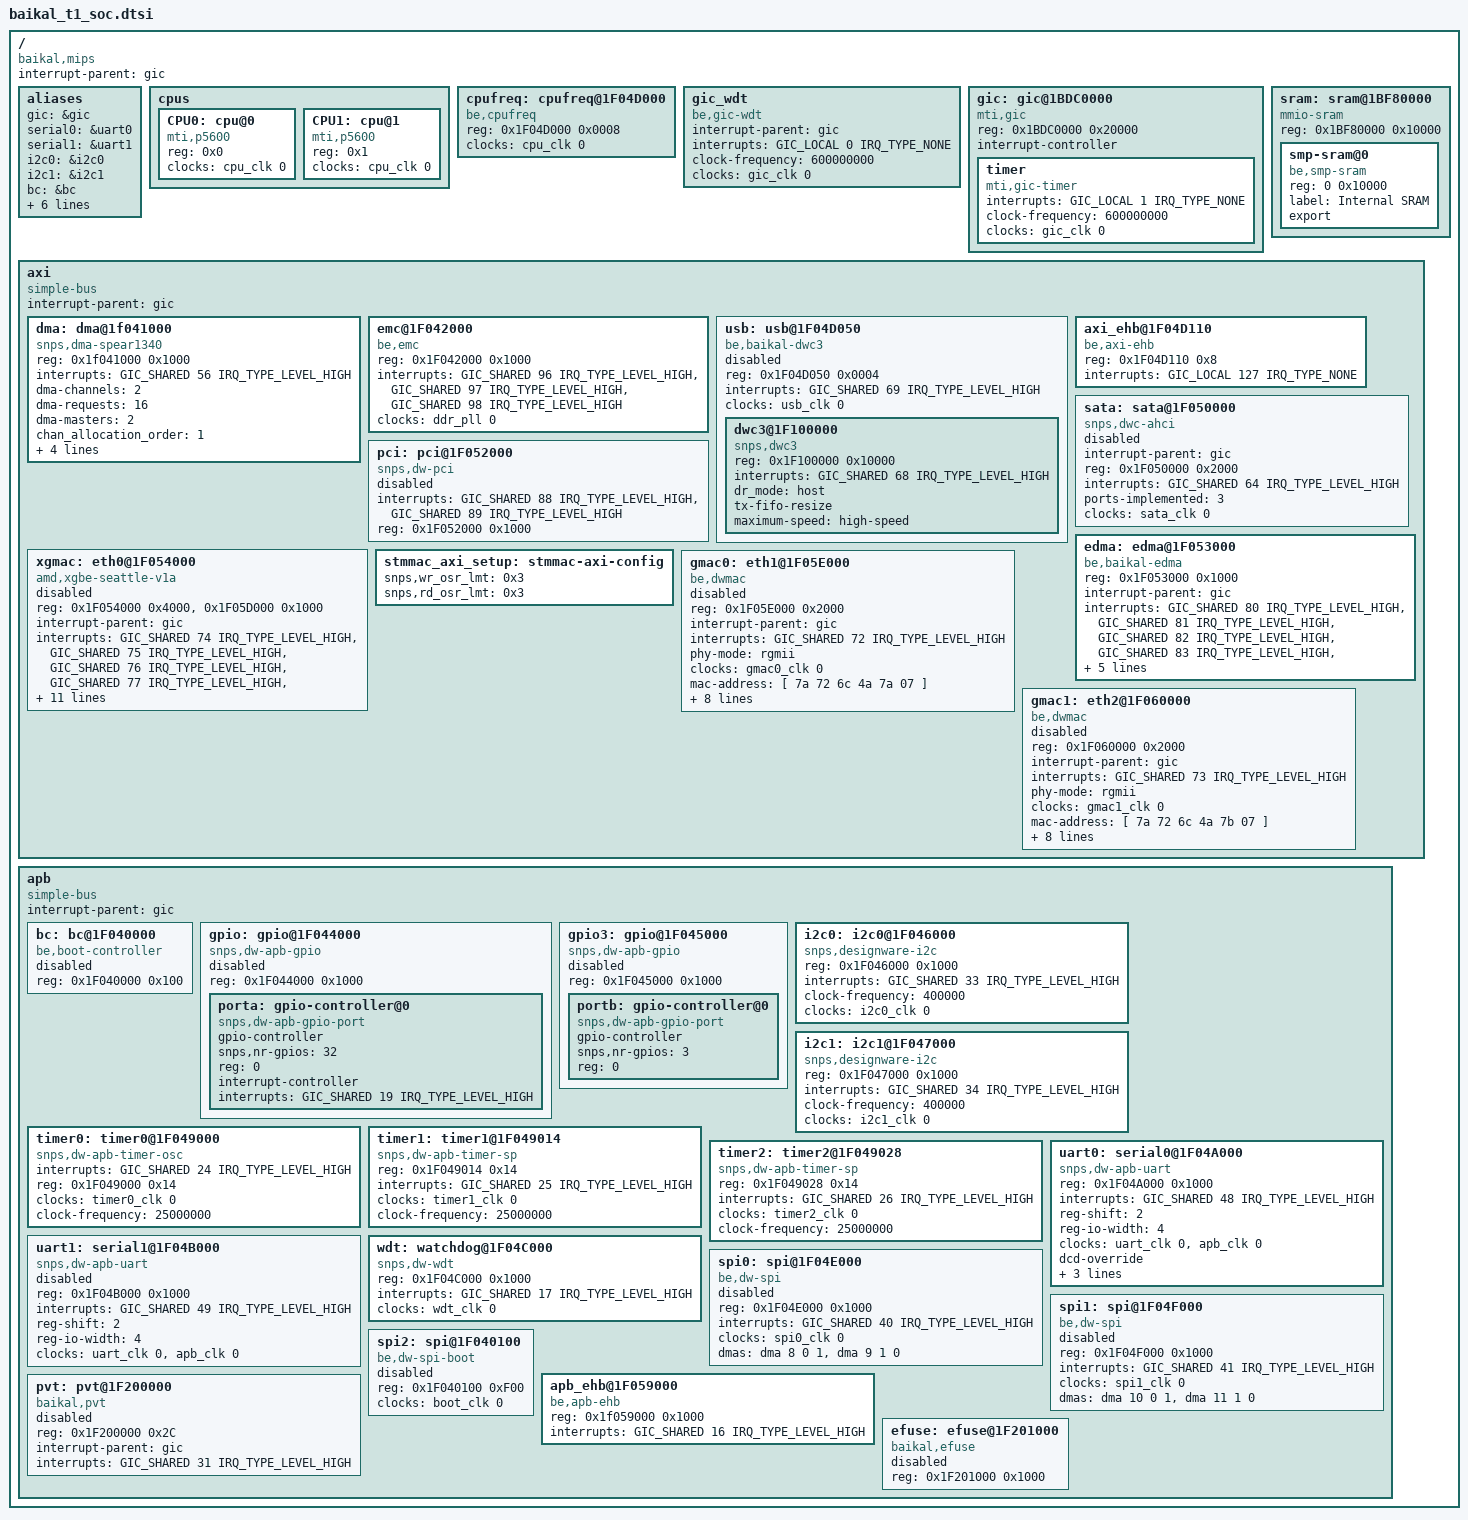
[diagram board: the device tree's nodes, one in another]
/*
 * Baikal-T1 SOC generic device tree
 *
 * Copyright (C) 2014-2017  Baikal Electronics JSC
 *
 * This program is free software; you can redistribute it and/or
 * modify it under the terms of the GNU General Public License
 * as published by the Free Software Foundation; either version 2
 * of the License, or (at your option) any later version.
 */

#include "baikal_t1_clocks.dtsi"

/ {

	compatible = "baikal,mips", "baikal,baikal-t1-soc";
	#address-cells = <1>;
	#size-cells = <1>;
 	interrupt-parent = <&gic>;

	aliases {
		gic = &gic;
		serial0 = &uart0;
		serial1 = &uart1;
		i2c0 = &i2c0;
		i2c1 = &i2c1;
		bc   = &bc;
		ssi0 = &spi0;
		ssi1 = &spi1;
		ssi2 = &spi2;
		ethernet0 = &gmac0;
		ethernet1 = &gmac1;
		ethernet2 = &xgmac;
	};

	cpus {
		#address-cells = <1>;
		#size-cells = <0>;

		CPU0: cpu@0 {
			device_type = "cpu";
			compatible = "mti,p5600";
			reg = <0x0>;
			clocks = <&cpu_clk 0>;
			clock-names = "cpuclk";
		};

		CPU1: cpu@1 {
			device_type = "cpu";
			compatible = "mti,p5600";
			reg = <0x1>;
			clocks = <&cpu_clk 0>;
			clock-names = "cpuclk";
		};
	};

	cpufreq: cpufreq@1F04D000 {
		compatible = "be,cpufreq";
		reg = <0x1F04D000 0x0008>;
		clocks = <&cpu_clk 0>;
		clock-names = "cpuclk";
	};

	gic_wdt: gic_wdt {
		compatible = "be,gic-wdt";
		interrupt-parent = <&gic>;
		interrupts = <GIC_LOCAL 0 IRQ_TYPE_NONE>;
		clock-frequency = <600000000>;
		clocks = <&gic_clk 0>;
		clock-names = "gicclk";

	};

	gic: gic@1BDC0000 {
		compatible = "mti,gic";
		reg = <0x1BDC0000 0x20000>;
		interrupt-controller;
		#interrupt-cells = <3>;

		timer:timer {
			compatible = "mti,gic-timer";
			interrupts = <GIC_LOCAL 1 IRQ_TYPE_NONE>;
			clock-frequency = <600000000>;
			clocks = <&gic_clk 0>;
			clock-names = "gicclk";
		};
	};

	sram: sram@1BF80000 {
		compatible = "mmio-sram";
		reg = <0x1BF80000 0x10000>;
		#address-cells = <1>;
		#size-cells = <1>;
		ranges = <0 0x1BF80000 0x10000>;

		smp-sram@0 {
			compatible = "be,smp-sram";
			reg = <0 0x10000>;
			label="Internal SRAM";
			export;
		};
	};

	axi {
		compatible = "simple-bus";
		#address-cells = <1>;
		#size-cells = <1>;
		interrupt-parent = <&gic>;

		ranges;

		dma: dma@1f041000 {
			compatible = "snps,dma-spear1340";
			reg = <0x1f041000 0x1000>;
			interrupts = <GIC_SHARED 56 IRQ_TYPE_LEVEL_HIGH>;
			dma-channels = <2>;
			dma-requests = <16>;
			dma-masters = <2>;
			#dma-cells = <3>;
			chan_allocation_order = <1>;
			chan_priority = <1>;
			block_size = <0xfff>;
			data_width = <0 0 0 0>;
			clocks = <&dma_clk 0>;
			clock-names = "hclk";
		};


		emc@1F042000 {
			compatible = "be,emc", "be,memory-controller";
			reg = <0x1F042000 0x1000>;
			interrupts = <GIC_SHARED 96 IRQ_TYPE_LEVEL_HIGH>,
						 <GIC_SHARED 97 IRQ_TYPE_LEVEL_HIGH>,
						 <GIC_SHARED 98 IRQ_TYPE_LEVEL_HIGH>;
			clocks = <&ddr_pll 0>;
			clock-names = "ddrclk";
		};

		usb: usb@1F04D050 {
			compatible = "be,baikal-dwc3";
			reg = <0x1F04D050 0x0004>;
			interrupts = <GIC_SHARED 69 IRQ_TYPE_LEVEL_HIGH>;
			#address-cells = <1>;
			#size-cells = <1>;
			clocks = <&usb_clk 0>;
			clock-names = "usb";
			ranges;
			status = "disabled";

			dwc3@1F100000 {
				compatible = "snps,dwc3", "synopsys,dwc3", "generic-xhci";
				reg = <0x1F100000 0x10000>;
				interrupts = <GIC_SHARED 68 IRQ_TYPE_LEVEL_HIGH>;
				dr_mode = "host";
				tx-fifo-resize;
				maximum-speed = "high-speed";
			};
		};

		axi_ehb@1F04D110 {
			compatible = "be,axi-ehb";
			reg = <0x1F04D110 0x8>;
			interrupts = <GIC_LOCAL 127 IRQ_TYPE_NONE>;
		};

		sata: sata@1F050000 {
			interrupt-parent = <&gic>;
			compatible = "snps,dwc-ahci", "generic-ahci";
			reg = <0x1F050000 0x2000>;
			interrupts = <GIC_SHARED 64 IRQ_TYPE_LEVEL_HIGH>;
			ports-implemented = <3>;
			clocks = <&sata_clk 0>;
			clock-names = "sataclk";
			status = "disabled";
		};

		pci: pci@1F052000 {
			compatible = "snps,dw-pci";
			interrupts = <GIC_SHARED 88 IRQ_TYPE_LEVEL_HIGH>,
						 <GIC_SHARED 89 IRQ_TYPE_LEVEL_HIGH>;
			reg = <0x1F052000 0x1000>;
			status = "disabled";
		};

		edma: edma@1F053000 {
			compatible = "be,baikal-edma";
			reg = <0x1F053000 0x1000>;
			interrupt-parent = <&gic>;
			interrupts = <GIC_SHARED 80 IRQ_TYPE_LEVEL_HIGH>,
					<GIC_SHARED 81 IRQ_TYPE_LEVEL_HIGH>,
					<GIC_SHARED 82 IRQ_TYPE_LEVEL_HIGH>,
					<GIC_SHARED 83 IRQ_TYPE_LEVEL_HIGH>,
					<GIC_SHARED 84 IRQ_TYPE_LEVEL_HIGH>,
					<GIC_SHARED 85 IRQ_TYPE_LEVEL_HIGH>,
					<GIC_SHARED 86 IRQ_TYPE_LEVEL_HIGH>,
					<GIC_SHARED 87 IRQ_TYPE_LEVEL_HIGH>;
			interrupt-names = "eDMA-Tx-0", "eDMA-Tx-1", "eDMA-Tx-2", "eDMA-Tx-3",
					"eDMA-Rx-0", "eDMA-Rx-1", "eDMA-Rx-2", "eDMA-Rx-3";
			upstream = <&pci>;
		};

		xgmac: eth0@1F054000 {
			compatible = "amd,xgbe-seattle-v1a";
			reg = <0x1F054000 0x4000>,
				  <0x1F05D000 0x1000>;
			interrupt-parent = <&gic>;
			interrupts = <GIC_SHARED 74 IRQ_TYPE_LEVEL_HIGH>,
						 <GIC_SHARED 75 IRQ_TYPE_LEVEL_HIGH>,
						 <GIC_SHARED 76 IRQ_TYPE_LEVEL_HIGH>,
						 <GIC_SHARED 77 IRQ_TYPE_LEVEL_HIGH>,
						 <GIC_SHARED 78 IRQ_TYPE_LEVEL_HIGH>,
						 <GIC_SHARED 79 IRQ_TYPE_LEVEL_HIGH>;
			fsl,num-rx-queues=<3>;
			clocks = <&xgmac_dma 0>, <&xgmac_ptp 0>, <&div_156m 0>;
			clock-names = "dma_clk", "ptp_clk", "xgbe_clk";
			be,external-clock;
			phy-mode = "xgmii";
			be,speed-set = <1>;
			be,mode-set = <0>;
			mac-address = [ 00 20 13 ba 1c a1 ];
			local-mac-address = [ 00 20 13 ba 1c a1 ];
			be,pcs-mode = "KR";
			status = "disabled";
		};

		stmmac_axi_setup: stmmac-axi-config {
			snps,wr_osr_lmt = <0x3>;
			snps,rd_osr_lmt = <0x3>;
		};


		gmac0: eth1@1F05E000 {
			compatible = "be,dwmac", "snps,dwmac-3.710", "snps,dwmac";
			reg = <0x1F05E000 0x2000>;
			interrupt-parent = <&gic>;
			interrupts = <GIC_SHARED 72 IRQ_TYPE_LEVEL_HIGH>;
			interrupt-names = "macirq";
			phy-mode = "rgmii";
			clocks = <&gmac0_clk 0>;
			clock-names = "stmmaceth";
			mac-address = [ 7a 72 6c 4a 7a 07 ];
			local-mac-address = [ 7a 72 6c 4a 7a 07 ];
			txd0-skew-ps = <0>;
			txd1-skew-ps = <0>;
			txd2-skew-ps = <0>;
			txd3-skew-ps = <0>;
			txc-skew-ps  = <0xff>;
			snps,pbl = <2>;
			snps,axi-config = <&stmmac_axi_setup>;
			status = "disabled";
		};

		gmac1: eth2@1F060000 {
			compatible = "be,dwmac", "snps,dwmac-3.710", "snps,dwmac";
			reg = <0x1F060000 0x2000>;
			interrupt-parent = <&gic>;
			interrupts = <GIC_SHARED 73 IRQ_TYPE_LEVEL_HIGH>;
			interrupt-names = "macirq";
			phy-mode = "rgmii";
			clocks = <&gmac1_clk 0>;
			clock-names = "stmmaceth";
			mac-address = [ 7a 72 6c 4a 7b 07 ];
			local-mac-address = [ 7a 72 6c 4a 7b 07 ];
			txd0-skew-ps = <0>;
			txd1-skew-ps = <0>;
			txd2-skew-ps = <0>;
			txd3-skew-ps = <0>;
			txc-skew-ps  = <0xff>;
			snps,pbl = <2>;
			snps,axi-config = <&stmmac_axi_setup>;
			status = "disabled";
		};
	}; /* axi */

	apb {
		compatible = "simple-bus";
		#address-cells = <1>;
		#size-cells = <1>;
		interrupt-parent = <&gic>;

		ranges;

		bc: bc@1F040000 {
			compatible = "be,boot-controller";
			reg = <0x1F040000 0x100>;
			status = "disabled";
		};

		gpio: gpio@1F044000 {
			compatible = "snps,dw-apb-gpio";
			reg = <0x1F044000 0x1000>;
			#address-cells = <1>;
			#size-cells = <0>;
			status = "disabled";

			porta: gpio-controller@0 {
				compatible = "snps,dw-apb-gpio-port";
				#gpio-cells = <2>;
				gpio-controller;
				snps,nr-gpios = <32>;
				reg = <0>;
				#interrupt-cells = <2>;
				interrupt-controller;
				interrupts = <GIC_SHARED 19 IRQ_TYPE_LEVEL_HIGH>;
			};
		};

		gpio3: gpio@1F045000 {
			compatible = "snps,dw-apb-gpio";
			reg = <0x1F045000 0x1000>;
			#address-cells = <1>;
			#size-cells = <0>;
			status = "disabled";

			portb: gpio-controller@0 {
				compatible = "snps,dw-apb-gpio-port";
				#gpio-cells = <2>;
				gpio-controller;
				snps,nr-gpios = <3>;
				reg = <0>;
			};
		};

		i2c0: i2c0@1F046000 {
			#address-cells = <1>;
			#size-cells = <0>;
			compatible = "snps,designware-i2c";
			reg = <0x1F046000 0x1000>;
			interrupts = <GIC_SHARED 33 IRQ_TYPE_LEVEL_HIGH>;
			clock-frequency = <400000>;
			clocks = <&i2c0_clk 0>;
			clock-names = "i2c0clk";
		};

		i2c1: i2c1@1F047000 {
			#address-cells = <1>;
			#size-cells = <0>;
			compatible = "snps,designware-i2c";
			reg = <0x1F047000 0x1000>;
			interrupts = <GIC_SHARED 34 IRQ_TYPE_LEVEL_HIGH>;
			clock-frequency = <400000>;
			clocks = <&i2c1_clk 0>;
			clock-names = "i2c1clk";
		};

		timer0: timer0@1F049000 {
			compatible = "snps,dw-apb-timer-osc";
			interrupts = <GIC_SHARED 24 IRQ_TYPE_LEVEL_HIGH>;
			reg = <0x1F049000 0x14>;
			clocks = <&timer0_clk 0>;
			clock-frequency  = <25000000>;
			clock-names = "timer";
		};

		timer1: timer1@1F049014 {
			compatible = "snps,dw-apb-timer-sp";
			reg = <0x1F049014 0x14>;
			interrupts = <GIC_SHARED 25 IRQ_TYPE_LEVEL_HIGH>;
			clocks = <&timer1_clk 0>;
			clock-frequency  = <25000000>;
			clock-names = "timer";
		};

		timer2: timer2@1F049028 {
			compatible = "snps,dw-apb-timer-sp";
			reg = <0x1F049028 0x14>;
			interrupts = <GIC_SHARED 26 IRQ_TYPE_LEVEL_HIGH>;
			clocks = <&timer2_clk 0>;
			clock-frequency  = <25000000>;
			clock-names = "timer";
		};

		uart0: serial0@1F04A000 {
			compatible = "snps,dw-apb-uart";
			reg = <0x1F04A000 0x1000>;
			interrupts = <GIC_SHARED 48 IRQ_TYPE_LEVEL_HIGH>;
			reg-shift = <2>;
			reg-io-width = <4>;
			clocks = <&uart_clk 0>, <&apb_clk 0>;
			clock-names = "baudclk", "apb_pclk";
			dcd-override;
			dsr-override;
			cts-override;
			ri-override;
		};

		uart1: serial1@1F04B000 {
			compatible = "snps,dw-apb-uart";
			reg = <0x1F04B000 0x1000>;
			interrupts = <GIC_SHARED 49 IRQ_TYPE_LEVEL_HIGH>;
			reg-shift = <2>;
			reg-io-width = <4>;
			clocks = <&uart_clk 0>, <&apb_clk 0>;
			clock-names = "baudclk", "apb_pclk";
			status = "disabled";
		};

		wdt: watchdog@1F04C000 {
			compatible = "snps,dw-wdt";
			reg = <0x1F04C000 0x1000>;
			interrupts = <GIC_SHARED 17 IRQ_TYPE_LEVEL_HIGH>;
			clocks = <&wdt_clk 0>;
			clock-names = "wdtclk";
		};

		spi0: spi@1F04E000 {
			compatible = "be,dw-spi";
			reg = <0x1F04E000 0x1000>;
			interrupts = <GIC_SHARED 40 IRQ_TYPE_LEVEL_HIGH>;
			clocks = <&spi0_clk 0>;
			clock-names = "spi0clk";
			dma-names = "tx", "rx";
			dmas = <&dma 8 0 1>, <&dma 9 1 0>;
			#address-cells = <1>;
			#size-cells = <0>;
			status = "disabled";
		};

		spi1: spi@1F04F000 {
			compatible = "be,dw-spi";
			reg = <0x1F04F000 0x1000>;
			interrupts = <GIC_SHARED 41 IRQ_TYPE_LEVEL_HIGH>;
			clocks = <&spi1_clk 0>;
			clock-names = "spi1clk";
			dma-names = "tx", "rx";
			dmas = <&dma 10 0 1>, <&dma 11 1 0>;
			#address-cells = <1>;
			#size-cells = <0>;
			status = "disabled";
		};

		spi2: spi@1F040100 {
			compatible = "be,dw-spi-boot";
			reg = <0x1F040100 0xF00>;
			clocks = <&boot_clk 0>;
			clock-names = "bootclk";
			#address-cells = <1>;
			#size-cells = <0>;
			status = "disabled";
		};

		apb_ehb@1F059000 {
			compatible = "be,apb-ehb";
			reg = <0x1f059000 0x1000>;
			interrupts = <GIC_SHARED 16 IRQ_TYPE_LEVEL_HIGH>;
		};

		pvt: pvt@1F200000 {
			compatible = "baikal,pvt";
			reg = <0x1F200000 0x2C>;
			interrupt-parent = <&gic>;
			interrupts = <GIC_SHARED 31 IRQ_TYPE_LEVEL_HIGH>;
			status = "disabled";
		};

		efuse: efuse@1F201000 {
			compatible = "baikal,efuse";
			reg = <0x1F201000 0x1000>;
			status = "disabled";
		};

	}; /* apb */

};
